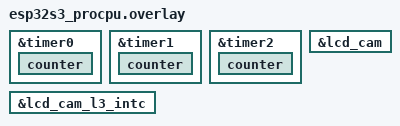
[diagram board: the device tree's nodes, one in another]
/*
 * Copyright (c) 2025 Espressif Systems (Shanghai) Co., Ltd.
 *
 * SPDX-License-Identifier: Apache-2.0
 */

&timer0 {
	status = "okay";

	counter {
		status = "okay";
	};
};

&timer1 {
	status = "okay";

	counter {
		status = "okay";
	};
};

&timer2 {
	status = "okay";

	counter {
		status = "okay";
	};
};

/*
 * The level-3 cases in mli_dispatch.c / mli_encoding.c are guarded on
 * lcd_cam_l3_intc being okay. It already defaults to okay in esp32s3_common.dtsi,
 * so without this the coverage is opt-out: adding status = "disabled" to either
 * node upstream would silently delete five test cases with no twister signal.
 * Enable them here so the dependency is deliberate.
 */
&lcd_cam {
	status = "okay";
};

&lcd_cam_l3_intc {
	status = "okay";
};
